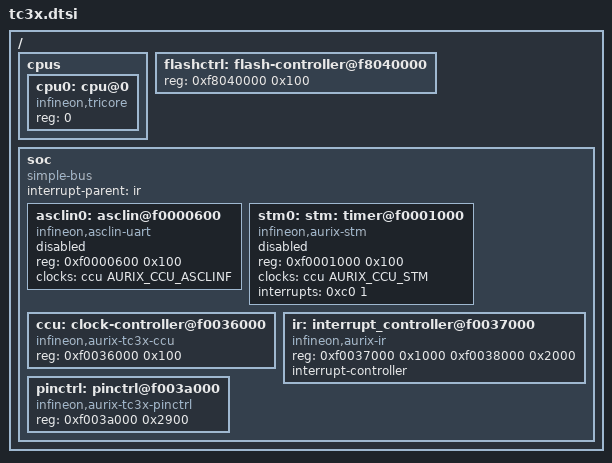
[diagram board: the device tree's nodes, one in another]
/*
 * SPDX-FileCopyrightText: Copyright (c) 2024 Infineon Technologies AG,
 * SPDX-FileCopyrightText: or an affiliate of Infineon Technologies AG. All rights reserved.
 * SPDX-FileCopyrightText: Copyright (c) 2026 Linumiz
 *
 * SPDX-License-Identifier: Apache-2.0
 */

#include <mem.h>
#include <freq.h>
#include <skeleton.dtsi>
#include <zephyr/dt-bindings/clock/infineon-aurix-ccu.h>

/* Peripherals at the same address on all TC3x devices */
/ {
	cpus {
		#address-cells = <1>;
		#size-cells = <0>;

		cpu0: cpu@0 {
			compatible = "infineon,tricore", "infineon,tc162";
			reg = <0>;
		};
	};

	flashctrl: flash-controller@f8040000 {
		reg = <0xf8040000 0x100>;
		ranges;
		#address-cells = <1>;
		#size-cells = <1>;
	};

	soc {
		#address-cells = <1>;
		#size-cells = <1>;
		interrupt-parent = <&ir>;
		compatible = "simple-bus";
		ranges;

		asclin0: asclin@f0000600 {
			compatible = "infineon,asclin-uart";
			reg = <0xf0000600 0x100>;
			clocks = <&ccu AURIX_CCU_ASCLINF>;
			status = "disabled";
		};

		stm0: stm: timer@f0001000 {
			compatible = "infineon,aurix-stm";
			reg = <0xf0001000 0x100>;
			clocks = <&ccu AURIX_CCU_STM>;
			interrupts = <0xc0 1>;
			status = "disabled";
		};

		ccu: clock-controller@f0036000 {
			compatible = "infineon,aurix-tc3x-ccu", "infineon,aurix-ccu";
			reg = <0xf0036000 0x100>;
			#clock-cells = <1>;
		};

		ir: interrupt_controller@f0037000 {
			compatible = "infineon,aurix-ir";
			reg = <0xf0037000 0x1000 0xf0038000 0x2000>;
			reg-names = "ir", "src";
			#address-cells = <0>;
			#interrupt-cells = <2>;
			interrupt-controller;
		};

		/* Ports P00 to P40 */
		pinctrl: pinctrl@f003a000 {
			compatible = "infineon,aurix-tc3x-pinctrl", "infineon,aurix-pinctrl";
			reg = <0xf003a000 0x2900>;
			#address-cells = <1>;
			#size-cells = <1>;
			ranges;
		};
	};
};
